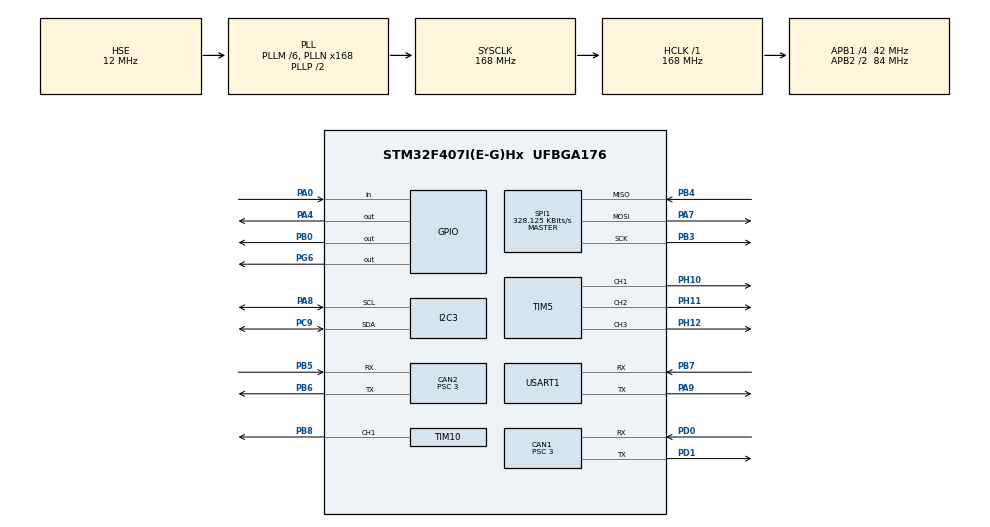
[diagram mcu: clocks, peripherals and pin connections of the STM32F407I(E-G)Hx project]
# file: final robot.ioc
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CAN1.BS1=CAN_BS1_10TQ
CAN1.BS2=CAN_BS2_3TQ
CAN1.CalculateBaudRate=1000000
CAN1.CalculateTimeQuantum=71.42857142857143
CAN1.Prescaler=3
CAN2.BS1=CAN_BS1_10TQ
CAN2.BS2=CAN_BS2_3TQ
CAN2.CalculateBaudRate=1000000
CAN2.CalculateTimeBit=1000
CAN2.CalculateTimeQuantum=71.42857142857143
CAN2.Prescaler=3
FREERTOS.Tasks01=ImuTask,3,1024,INS_task,Default,NULL,Dynamic,NULL,NULL;ChassisTask,1,1024,chassis_task,Default,NULL,Dynamic,NULL,NULL
I2C3.I2C_Mode=I2C_Fast
Mcu.Family=STM32F4
Mcu.Name=STM32F407I(E-G)Hx
Mcu.Package=UFBGA176
NVIC.CAN1_RX0_IRQn=true\:5\:0\:true\:false\:true\:true\:true\:true
NVIC.CAN2_RX0_IRQn=true\:5\:0\:false\:false\:true\:true\:true\:true
NVIC.PriorityGroup=NVIC_PRIORITYGROUP_4
PA0-WKUP.GPIO_PuPd=GPIO_PULLDOWN
PA0-WKUP.Signal=GPIO_Input
PA13.Mode=Serial_Wire
PA13.Signal=SYS_JTMS-SWDIO
PA14.Mode=Serial_Wire
PA14.Signal=SYS_JTCK-SWCLK
PA4.GPIO_ModeDefaultOutputPP=GPIO_MODE_OUTPUT_PP
PA4.GPIO_PuPd=GPIO_PULLUP
PA4.GPIO_Speed=GPIO_SPEED_FREQ_HIGH
PA4.PinState=GPIO_PIN_SET
PA4.Signal=GPIO_Output
PA7.GPIO_Mode=GPIO_MODE_AF_PP
PA7.GPIO_PuPd=GPIO_NOPULL
PA7.GPIO_Speed=GPIO_SPEED_FREQ_VERY_HIGH
PA7.Mode=Full_Duplex_Master
PA7.Signal=SPI1_MOSI
PA8.GPIO_Mode=GPIO_MODE_AF_OD
PA8.GPIO_Pu=GPIO_PULLUP
PA8.GPIO_Speed=GPIO_SPEED_FREQ_VERY_HIGH
PA8.Mode=I2C
PA8.Signal=I2C3_SCL
PA9.GPIO_PuPd=GPIO_PULLUP
PA9.Mode=Asynchronous
PA9.Signal=USART1_TX
PB0.GPIO_ModeDefaultOutputPP=GPIO_MODE_OUTPUT_PP
PB0.GPIO_PuPd=GPIO_PULLUP
PB0.GPIO_Speed=GPIO_SPEED_FREQ_HIGH
PB0.PinState=GPIO_PIN_SET
PB0.Signal=GPIO_Output
PB3.GPIO_Mode=GPIO_MODE_AF_PP
PB3.GPIO_PuPd=GPIO_NOPULL
PB3.GPIO_Speed=GPIO_SPEED_FREQ_VERY_HIGH
PB3.Mode=Full_Duplex_Master
PB3.Signal=SPI1_SCK
PB4.GPIO_Mode=GPIO_MODE_AF_PP
PB4.GPIO_PuPd=GPIO_NOPULL
PB4.GPIO_Speed=GPIO_SPEED_FREQ_VERY_HIGH
PB4.Mode=Full_Duplex_Master
PB4.Signal=SPI1_MISO
PB5.Mode=CAN_Activate
PB5.Signal=CAN2_RX
PB6.Mode=CAN_Activate
PB6.Signal=CAN2_TX
PB7.GPIO_PuPd=GPIO_PULLUP
PB7.Mode=Asynchronous
PB7.Signal=USART1_RX
PB8.GPIO_PuPd=GPIO_PULLUP
PB8.GPIO_Speed=GPIO_SPEED_FREQ_HIGH
PB8.Signal=S_TIM10_CH1
PC9.GPIO_Mode=GPIO_MODE_AF_OD
PC9.GPIO_Pu=GPIO_PULLUP
PC9.GPIO_Speed=GPIO_SPEED_FREQ_VERY_HIGH
PC9.Mode=I2C
PC9.Signal=I2C3_SDA
PD0.Mode=CAN_Activate
PD0.Signal=CAN1_RX
PD1.Mode=CAN_Activate
PD1.Signal=CAN1_TX
PG6.GPIO_ModeDefaultOutputPP=GPIO_MODE_OUTPUT_PP
PG6.GPIO_PuPd=GPIO_PULLUP
PG6.GPIO_Speed=GPIO_SPEED_FREQ_MEDIUM
PG6.PinState=GPIO_PIN_SET
PG6.Signal=GPIO_Output
PH0-OSC_IN.Mode=HSE-External-Oscillator
PH0-OSC_IN.Signal=RCC_OSC_IN
PH1-OSC_OUT.Mode=HSE-External-Oscillator
PH1-OSC_OUT.Signal=RCC_OSC_OUT
PH10.GPIO_ModeDefaultPP=GPIO_MODE_AF_PP
PH10.GPIO_PuPd=GPIO_PULLUP
PH10.GPIO_Speed=GPIO_SPEED_FREQ_HIGH
PH10.Signal=S_TIM5_CH1
PH11.GPIO_ModeDefaultPP=GPIO_MODE_AF_PP
PH11.GPIO_PuPd=GPIO_PULLUP
PH11.GPIO_Speed=GPIO_SPEED_FREQ_HIGH
PH11.Signal=S_TIM5_CH2
PH12.GPIO_ModeDefaultPP=GPIO_MODE_AF_PP
PH12.GPIO_PuPd=GPIO_PULLUP
PH12.GPIO_Speed=GPIO_SPEED_FREQ_HIGH
PH12.Signal=S_TIM5_CH3
ProjectManager.HeapSize=0x200
ProjectManager.StackSize=0x400
ProjectManager.TargetToolchain=MDK-ARM V5
RCC.48MHZClocksFreq_Value=84000000
RCC.AHBFreq_Value=168000000
RCC.APB1CLKDivider=RCC_HCLK_DIV4
RCC.APB1Freq_Value=42000000
RCC.APB1TimFreq_Value=84000000
RCC.APB2CLKDivider=RCC_HCLK_DIV2
RCC.APB2Freq_Value=84000000
RCC.APB2TimFreq_Value=168000000
RCC.CortexFreq_Value=168000000
RCC.HCLKFreq_Value=168000000
RCC.HSE_VALUE=12000000
RCC.HSI_VALUE=16000000
RCC.LSE_VALUE=32768
RCC.PLLM=6
RCC.PLLN=168
RCC.PLLSourceVirtual=RCC_PLLSOURCE_HSE
RCC.SYSCLKFreq_VALUE=168000000
RCC.SYSCLKSource=RCC_SYSCLKSOURCE_PLLCLK
RCC.VCOOutputFreq_Value=336000000
SH.S_TIM10_CH1.0=TIM10_CH1,PWM Generation1 CH1
SH.S_TIM5_CH1.0=TIM5_CH1,PWM Generation1 CH1
SH.S_TIM5_CH2.0=TIM5_CH2,PWM Generation2 CH2
SH.S_TIM5_CH3.0=TIM5_CH3,PWM Generation3 CH3
SPI1.BaudRatePrescaler=SPI_BAUDRATEPRESCALER_256
SPI1.CLKPhase=SPI_PHASE_2EDGE
SPI1.CLKPolarity=SPI_POLARITY_HIGH
SPI1.CalculateBaudRate=328.125 KBits/s
SPI1.Direction=SPI_DIRECTION_2LINES
SPI1.Mode=SPI_MODE_MASTER
SPI1.VirtualType=VM_MASTER
TIM10.Channel=TIM_CHANNEL_1
TIM5.Channel-PWM\ Generation1\ CH1=TIM_CHANNEL_1
TIM5.Channel-PWM\ Generation2\ CH2=TIM_CHANNEL_2
TIM5.Channel-PWM\ Generation3\ CH3=TIM_CHANNEL_3
USART1.VirtualMode=VM_ASYNC
VP_FREERTOS_VS_CMSIS_V1.Mode=CMSIS_V1
VP_TIM10_VS_ClockSourceINT.Mode=Enable_Timer
board=custom

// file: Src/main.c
/* USER CODE BEGIN Header */
/**
  ******************************************************************************
  * @file           : main.c
  * @brief          : Main program body
  ******************************************************************************
  * @attention
  *
  * <h2><center>&copy; Copyright (c) 2019 STMicroelectronics.
  * All rights reserved.</center></h2>
  *
  * This software component is licensed by ST under BSD 3-Clause license,
  * the "License"; You may not use this file except in compliance with the
  * License. You may obtain a copy of the License at:
  *                        opensource.org/licenses/BSD-3-Clause
  *
  ******************************************************************************
  */
/* USER CODE END Header */
#include "main.h"
#include "cmsis_os.h"
#include "can.h"
#include "i2c.h"
#include "spi.h"
#include "tim.h"
#include "usart.h"
#include "gpio.h"

/* USER CODE BEGIN Includes */
#include "bsp_can.h"
#include "CAN_receive.h"
/* USER CODE END Includes */

/* USER CODE BEGIN PV */
uint8_t counter=0;
int corrente = 0;
/* USER CODE END PV */

void SystemClock_Config(void);
void MX_FREERTOS_Init(void);

int main(void)
{

  /* MCU Configuration--------------------------------------------------------*/

  /* Reset of all peripherals, Initializes the Flash interface and the Systick. */
  HAL_Init();

  /* Configure the system clock */
  SystemClock_Config();

  /* Initialize all configured peripherals */
  MX_GPIO_Init();
  MX_CAN1_Init();
  MX_USART1_UART_Init();
  MX_I2C3_Init();
  MX_SPI1_Init();
  MX_TIM5_Init();
  MX_TIM10_Init();
  MX_CAN2_Init();
  /* USER CODE BEGIN 2 */
  can_filter_init();
  /* USER CODE END 2 */

  /* Call init function for freertos objects (in freertos.c) */
  MX_FREERTOS_Init();
  /* Start scheduler */
  osKernelStart();

  /* We should never get here as control is now taken by the scheduler */
  /* Infinite loop */
  while (1)
  {

 }
}

void SystemClock_Config(void)
{
  RCC_OscInitTypeDef RCC_OscInitStruct = {0};
  RCC_ClkInitTypeDef RCC_ClkInitStruct = {0};

  /** Configure the main internal regulator output voltage
  */
  __HAL_RCC_PWR_CLK_ENABLE();
  __HAL_PWR_VOLTAGESCALING_CONFIG(PWR_REGULATOR_VOLTAGE_SCALE1);
  /** Initializes the RCC Oscillators according to the specified parameters
  * in the RCC_OscInitTypeDef structure.
  */
  RCC_OscInitStruct.OscillatorType = RCC_OSCILLATORTYPE_HSE;
  RCC_OscInitStruct.HSEState = RCC_HSE_ON;
  RCC_OscInitStruct.PLL.PLLState = RCC_PLL_ON;
  RCC_OscInitStruct.PLL.PLLSource = RCC_PLLSOURCE_HSE;
  RCC_OscInitStruct.PLL.PLLM = 6;
  RCC_OscInitStruct.PLL.PLLN = 168;
  RCC_OscInitStruct.PLL.PLLP = RCC_PLLP_DIV2;
  RCC_OscInitStruct.PLL.PLLQ = 4;
  if (HAL_RCC_OscConfig(&RCC_OscInitStruct) != HAL_OK)
  {
    Error_Handler();
  }
  /** Initializes the CPU, AHB and APB buses clocks
  */
  RCC_ClkInitStruct.ClockType = RCC_CLOCKTYPE_HCLK|RCC_CLOCKTYPE_SYSCLK
                              |RCC_CLOCKTYPE_PCLK1|RCC_CLOCKTYPE_PCLK2;
  RCC_ClkInitStruct.SYSCLKSource = RCC_SYSCLKSOURCE_PLLCLK;
  RCC_ClkInitStruct.AHBCLKDivider = RCC_SYSCLK_DIV1;
  RCC_ClkInitStruct.APB1CLKDivider = RCC_HCLK_DIV4;
  RCC_ClkInitStruct.APB2CLKDivider = RCC_HCLK_DIV2;

  if (HAL_RCC_ClockConfig(&RCC_ClkInitStruct, FLASH_LATENCY_5) != HAL_OK)
  {
    Error_Handler();
  }
}

void Error_Handler(void)
{
}

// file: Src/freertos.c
/* USER CODE BEGIN Header */
/**
  ******************************************************************************
  * File Name          : freertos.c
  * Description        : Code for freertos applications
  ******************************************************************************
  * @attention
  *
  * Copyright (c) 2022 STMicroelectronics.
  * All rights reserved.
  *
  * This software is licensed under terms that can be found in the LICENSE file
  * in the root directory of this software component.
  * If no LICENSE file comes with this software, it is provided AS-IS.
  *
  ******************************************************************************
  */
/* USER CODE END Header */

#include "FreeRTOS.h"
#include "task.h"
#include "main.h"
#include "cmsis_os.h"

osThreadId ImuTaskHandle;
osThreadId ChassisTaskHandle;

void INS_task(void const * argument);
void chassis_task(void const * argument);

void MX_FREERTOS_Init(void); /* (MISRA C 2004 rule 8.1) */

/* GetIdleTaskMemory prototype (linked to static allocation support) */
void vApplicationGetIdleTaskMemory( StaticTask_t **ppxIdleTaskTCBBuffer, StackType_t **ppxIdleTaskStackBuffer, uint32_t *pulIdleTaskStackSize );

/* USER CODE BEGIN GET_IDLE_TASK_MEMORY */
static StaticTask_t xIdleTaskTCBBuffer;
static StackType_t xIdleStack[configMINIMAL_STACK_SIZE];

void vApplicationGetIdleTaskMemory( StaticTask_t **ppxIdleTaskTCBBuffer, StackType_t **ppxIdleTaskStackBuffer, uint32_t *pulIdleTaskStackSize )
{
  *ppxIdleTaskTCBBuffer = &xIdleTaskTCBBuffer;
  *ppxIdleTaskStackBuffer = &xIdleStack[0];
  *pulIdleTaskStackSize = configMINIMAL_STACK_SIZE;
  /* place for user code */
}
/* USER CODE END GET_IDLE_TASK_MEMORY */

void MX_FREERTOS_Init(void) {

  /* Create the thread(s) */
  /* definition and creation of ImuTask */
  osThreadDef(ImuTask, INS_task, osPriorityRealtime, 0, 1024);
  ImuTaskHandle = osThreadCreate(osThread(ImuTask), NULL);

  /* definition and creation of ChassisTask */
  osThreadDef(ChassisTask, chassis_task, osPriorityAboveNormal, 0, 1024);
  ChassisTaskHandle = osThreadCreate(osThread(ChassisTask), NULL);

}
